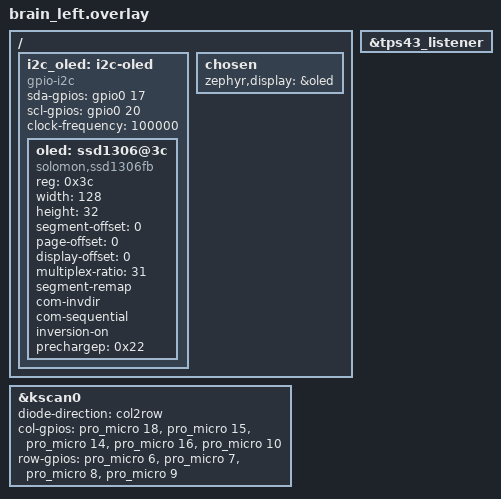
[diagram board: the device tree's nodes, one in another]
/*
 * Copyright (c) 2022 Duccio Breschi
 * Copyright (c) 2023 iamDrakkir
 * SPDX-License-Identifier: MIT
 */

#include "brain.dtsi"

/ {
    i2c_oled: i2c-oled {
        compatible = "gpio-i2c";
        sda-gpios = <&gpio0 17 (GPIO_OPEN_DRAIN | GPIO_PULL_UP)>;
        scl-gpios = <&gpio0 20 (GPIO_OPEN_DRAIN | GPIO_PULL_UP)>;
        clock-frequency = <100000>;
        #address-cells = <1>;
        #size-cells = <0>;

        oled: ssd1306@3c {
            compatible = "solomon,ssd1306fb";
            reg = <0x3c>;
            width = <128>;
            height = <32>;
            segment-offset = <0>;
            page-offset = <0>;
            display-offset = <0>;
            multiplex-ratio = <31>;
            segment-remap;
            com-invdir;
            com-sequential;
            inversion-on;
            prechargep = <0x22>;
        };
    };

    chosen {
        zephyr,display = &oled;
    };
};

&tps43_listener {
    status = "okay";
};

&kscan0 {
    diode-direction = "col2row";
    col-gpios
        = <&pro_micro 18 (GPIO_ACTIVE_HIGH)> // COL0
        , <&pro_micro 15 (GPIO_ACTIVE_HIGH)> // COL1
        , <&pro_micro 14 (GPIO_ACTIVE_HIGH)> // COL2
        , <&pro_micro 16 (GPIO_ACTIVE_HIGH)> // COL3
        , <&pro_micro 10 (GPIO_ACTIVE_HIGH)> // COL4
    ;
    row-gpios
        = <&pro_micro 6 (GPIO_ACTIVE_HIGH | GPIO_PULL_DOWN)> // ROW0
        , <&pro_micro 7 (GPIO_ACTIVE_HIGH | GPIO_PULL_DOWN)> // ROW1
        , <&pro_micro 8 (GPIO_ACTIVE_HIGH | GPIO_PULL_DOWN)> // ROW2
        , <&pro_micro 9 (GPIO_ACTIVE_HIGH | GPIO_PULL_DOWN)> // ROW3
    ;
};
